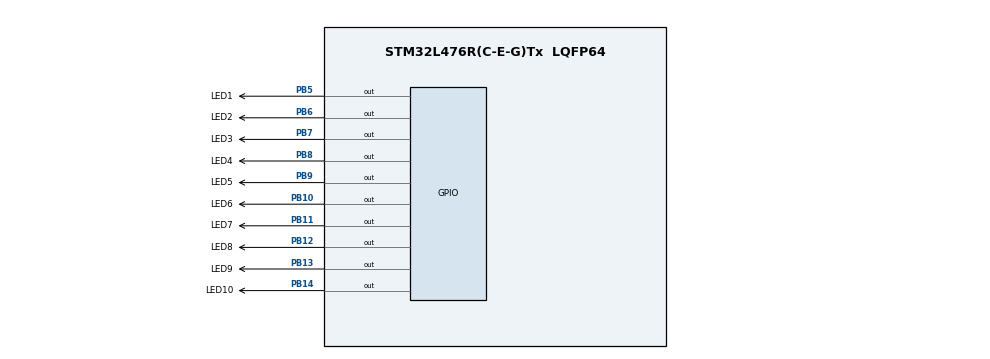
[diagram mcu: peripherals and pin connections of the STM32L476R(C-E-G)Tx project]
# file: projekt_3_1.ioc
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Mcu.Family=STM32L4
Mcu.Name=STM32L476R(C-E-G)Tx
Mcu.Package=LQFP64
NVIC.PriorityGroup=NVIC_PRIORITYGROUP_4
PB10.GPIO_Label=LED6
PB10.Signal=GPIO_Output
PB11.GPIO_Label=LED7
PB11.Signal=GPIO_Output
PB12.GPIO_Label=LED8
PB12.Signal=GPIO_Output
PB13.GPIO_Label=LED9
PB13.Signal=GPIO_Output
PB14.GPIO_Label=LED10
PB14.Signal=GPIO_Output
PB5.GPIO_Label=LED1
PB5.PinState=GPIO_PIN_RESET
PB5.Signal=GPIO_Output
PB6.GPIO_Label=LED2
PB6.Signal=GPIO_Output
PB7.GPIO_Label=LED3
PB7.Signal=GPIO_Output
PB8.GPIO_Label=LED4
PB8.Signal=GPIO_Output
PB9.GPIO_Label=LED5
PB9.Signal=GPIO_Output
ProjectManager.HeapSize=0x200
ProjectManager.StackSize=0x400
ProjectManager.TargetToolchain=STM32CubeIDE
RCC.HSE_VALUE=8000000
RCC.HSI_VALUE=16000000
RCC.LSE_VALUE=32768
RCC.MSI_VALUE=4000000
RCC.VCOOutputFreq_Value=32000000
board=custom

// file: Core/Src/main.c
/* USER CODE BEGIN Header */
/**
  ******************************************************************************
  * @file           : main.c
  * @brief          : Main program body
  ******************************************************************************
  * @attention
  *
  * Copyright (c) 2025 STMicroelectronics.
  * All rights reserved.
  *
  * This software is licensed under terms that can be found in the LICENSE file
  * in the root directory of this software component.
  * If no LICENSE file comes with this software, it is provided AS-IS.
  *
  ******************************************************************************
  */
/* USER CODE END Header */
#include "main.h"

void SystemClock_Config(void);
static void MX_GPIO_Init(void);

int main(void)
{

  /* MCU Configuration--------------------------------------------------------*/

  /* Reset of all peripherals, Initializes the Flash interface and the Systick. */
  HAL_Init();

  /* Configure the system clock */
  SystemClock_Config();

  /* Initialize all configured peripherals */
  MX_GPIO_Init();

  /* Infinite loop */
  /* USER CODE BEGIN WHILE */
  while (1)
  {
	  for (int i = 0; i < 10; i++){
		  HAL_GPIO_WritePin(LED1_GPIO_Port, LED1_Pin << i, GPIO_PIN_SET);
		  HAL_Delay(100);
		  HAL_GPIO_WritePin(LED1_GPIO_Port, LED1_Pin << i, GPIO_PIN_RESET);
	  }
    /* USER CODE END WHILE */

  }
}

void SystemClock_Config(void)
{
  RCC_OscInitTypeDef RCC_OscInitStruct = {0};
  RCC_ClkInitTypeDef RCC_ClkInitStruct = {0};

  /** Configure the main internal regulator output voltage
  */
  if (HAL_PWREx_ControlVoltageScaling(PWR_REGULATOR_VOLTAGE_SCALE1) != HAL_OK)
  {
    Error_Handler();
  }

  /** Initializes the RCC Oscillators according to the specified parameters
  * in the RCC_OscInitTypeDef structure.
  */
  RCC_OscInitStruct.OscillatorType = RCC_OSCILLATORTYPE_MSI;
  RCC_OscInitStruct.MSIState = RCC_MSI_ON;
  RCC_OscInitStruct.MSICalibrationValue = 0;
  RCC_OscInitStruct.MSIClockRange = RCC_MSIRANGE_6;
  RCC_OscInitStruct.PLL.PLLState = RCC_PLL_NONE;
  if (HAL_RCC_OscConfig(&RCC_OscInitStruct) != HAL_OK)
  {
    Error_Handler();
  }

  /** Initializes the CPU, AHB and APB buses clocks
  */
  RCC_ClkInitStruct.ClockType = RCC_CLOCKTYPE_HCLK|RCC_CLOCKTYPE_SYSCLK
                              |RCC_CLOCKTYPE_PCLK1|RCC_CLOCKTYPE_PCLK2;
  RCC_ClkInitStruct.SYSCLKSource = RCC_SYSCLKSOURCE_MSI;
  RCC_ClkInitStruct.AHBCLKDivider = RCC_SYSCLK_DIV1;
  RCC_ClkInitStruct.APB1CLKDivider = RCC_HCLK_DIV1;
  RCC_ClkInitStruct.APB2CLKDivider = RCC_HCLK_DIV1;

  if (HAL_RCC_ClockConfig(&RCC_ClkInitStruct, FLASH_LATENCY_0) != HAL_OK)
  {
    Error_Handler();
  }
}

static void MX_GPIO_Init(void)
{
  GPIO_InitTypeDef GPIO_InitStruct = {0};

  /* GPIO Ports Clock Enable */
  __HAL_RCC_GPIOB_CLK_ENABLE();

  /*Configure GPIO pin Output Level */
  HAL_GPIO_WritePin(GPIOB, LED6_Pin|LED7_Pin|LED8_Pin|LED9_Pin
                          |LED10_Pin|LED1_Pin|LED2_Pin|LED3_Pin
                          |LED4_Pin|LED5_Pin, GPIO_PIN_RESET);

  /*Configure GPIO pins : LED6_Pin LED7_Pin LED8_Pin LED9_Pin
                           LED10_Pin LED1_Pin LED2_Pin LED3_Pin
                           LED4_Pin LED5_Pin */
  GPIO_InitStruct.Pin = LED6_Pin|LED7_Pin|LED8_Pin|LED9_Pin
                          |LED10_Pin|LED1_Pin|LED2_Pin|LED3_Pin
                          |LED4_Pin|LED5_Pin;
  GPIO_InitStruct.Mode = GPIO_MODE_OUTPUT_PP;
  GPIO_InitStruct.Pull = GPIO_NOPULL;
  GPIO_InitStruct.Speed = GPIO_SPEED_FREQ_LOW;
  HAL_GPIO_Init(GPIOB, &GPIO_InitStruct);

}

void Error_Handler(void)
{
  __disable_irq();
  while (1)
  {
  }
}
